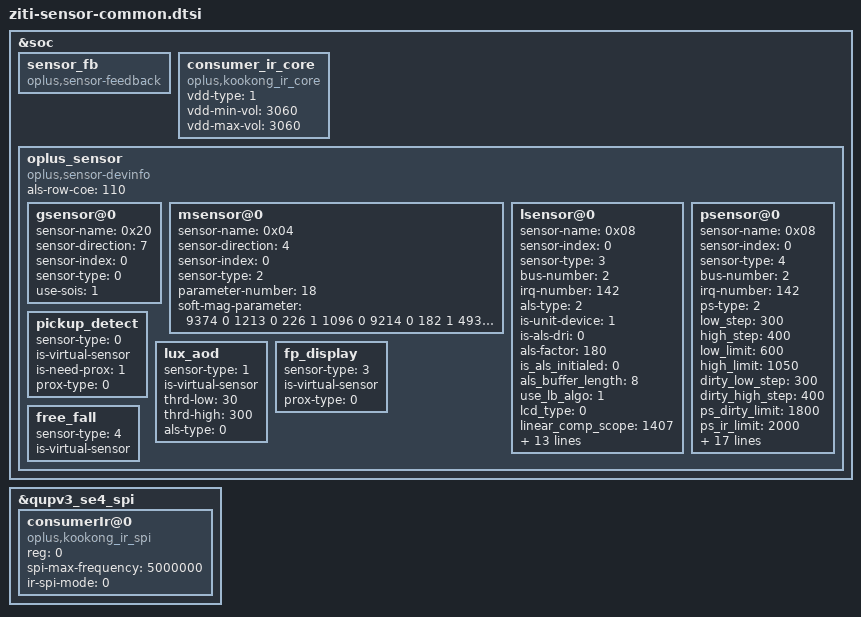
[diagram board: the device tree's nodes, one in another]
// SPDX-License-Identifier: GPL-2.0-only
/*
 * Copyright (C) 2018-2020 Oplus. All rights reserved.
 */

&soc {
        //#ifdef OPLUS_FEATURE_SENSOR_DRIVER
        sensor_fb: sensor_fb {
            compatible = "oplus,sensor-feedback";
        };
        consumer_ir_core: consumer_ir_core {
		compatible = "oplus,kookong_ir_core";
		status = "okay";

		vdd-type = <1>; /*0: internal LDO , 1: external LDO*/
		vdd-min-vol = <3060>;
		vdd-max-vol = <3060>;
	};
        /*enum sensor_id { OPLUS_ACCEL,OPLUS_GYRO,OPLUS_MAG,OPLUS_LIGHT,OPLUS_PROXIMITY,OPLUS_SAR,OPLUS_CT,OPLUS_BAROMETER,SENSORS_NUM};*/
        oplus_sensor: oplus_sensor {
                compatible = "oplus,sensor-devinfo";
                als-row-coe = <110>;
                /*enum {LSM6DSM = 0x01, BMI160 = 0x02, LSM6DS3 = 0x04, BMI260 = 0x08};*/
                gsensor@0 {
                        sensor-name = <0x20>;//ICM4X6XX
                        sensor-direction = <7>;
                        sensor-index = <0>;//source num
                        sensor-type = <0>;//OPLUS_ACCEL
                        use-sois = <1>;
                };
                /* enum {AKM0991X = 0x01, MMC5603 = 0x02};*/
                msensor@0 {
                        sensor-name = <0x04>;//MXG4300
                        sensor-direction = <4>;
                        sensor-index = <0>;
                        sensor-type = <2>;//OPLUS_MAG
                        parameter-number= <18>;
                        soft-mag-parameter = <9374 0 1213 0 226 1 1096 0 9214 0 182 1 493 0 677 1 10723 0>;//e00 sign e01 sign...
                };
                /*enum {STK3A5X=0x01,TCS3701=0x02,TCS3408=0x04,STK326X};*/
                /*enum {NORMAL=0x01,UNDER_LCD=0x02,VIRTUAL_UNDER_LCD=0x03}*/
		lsensor@0 {
			sensor-name = <0x08>;//stk3a6x
			sensor-index = <0>;
			sensor-type = <3>;//OPLUS_ALS
			bus-number = <2>;
			irq-number = <142>;
			als-type = <2>;//UNDER_LCD
			is-unit-device = <1>;
			is-als-dri = <0>;
			als-factor = <180>;
			is_als_initialed = <0>;
			als_buffer_length = <8>;
			use_lb_algo = <1>;
			lcd_type = <0>;
			linear_comp_scope = <1407>;
			linear_comp_intercept = <19873>;
			temp_lux = <0>;
			coef = <730>;
			bal_coef = <280>;
			ir_coef_stage_0 = <100>;
			ir_coef_stage_1 = <180>;
			ir_coef_stage_2 = <250>;
			ir_coef_stage_3 = <400>;
			ir_coef_val_0 = <1000>;
			ir_coef_val_1 = <500>;
			ir_coef_val_2 = <280>;
			ir_coef_val_3 = <180>;
			ir_coef_val_4 = <150>;
		};
		psensor@0 {
			sensor-name = <0x08>;//stk3a6x
			sensor-index = <0>;
			sensor-type = <4>;//OPLUS_PROXIMITY
			bus-number = <2>;
			irq-number = <142>;
			ps-type = <2>;
			low_step = <300>;
			high_step = <400>;
			low_limit = <600>;
			high_limit = <1050>;
			dirty_low_step = <300>;
			dirty_high_step = <400>;
			ps_dirty_limit = <1800>;
			ps_ir_limit = <2000>;
			ps_adjust_min = <0>;
			ps_adjust_max = <1850>;
			sampling_count = <5>;
			step_max = <400>;
			step_min = <100>;
			step_div = <2000>;
			anti_shake_delta = <70>;
			dynamic_cali_max = <2000>;
			raw2offset_radio = <1000>;
			offset_max = <60000>;
			offset_range_min = <0>;
			offset_range_max = <65535>;
			force_cali_limit = <2000>;
			cali_jitter_limit = <20>;
			cal_offset_margin = <3000>;
			parameter-number = <2>;
			sensor-reg = <0x03 0x60>; //override special reg
		};
                /*virtual sensor
                enum sensor_algo_id {
                        OPLUS_PICKUP_DETECT,
                        OPLUS_LUX_AOD,
                        OPLUS_TP_GESTURE,
                        OPLUS_FP_DISPLAY,
                        OPLUS_FREE_FALL,
                        OPLUS_CAMERA_PROTECT,
                        SENSOR_ALGO_NUM
                }*/
                pickup_detect {
                        sensor-type = <0>; //OPLUS_PICKUP_DETECT
                        is-virtual-sensor;
                        is-need-prox = <1>;
                        prox-type = <0>; // 0 - proximity; 1 - proximity_fake
                };
                lux_aod {
                        sensor-type = <1>; //OPLUS_LUX_AOD
                        is-virtual-sensor;
                        thrd-low = <30>;
                        thrd-high = <300>;
                        als-type = <0>; // 0 - wise_light; 1 - ambient_light
                };
                fp_display {
                        sensor-type = <3>; //OPLUS_FP_DISPLAY
                        is-virtual-sensor;
                        prox-type = <0>; // 0 - proximity; 1 - proximity_fake
                };
                free_fall {
                        sensor-type = <4>; //OPLUS_FREE_FALL
                        is-virtual-sensor;
                };
        };
        //#endif /*OPLUS_FEATURE_SENSOR_DRIVER*/
};

&qupv3_se4_spi {
	status = "ok";
	consumerIr@0 {
		compatible = "oplus,kookong_ir_spi";
		reg = <0>;
		status = "ok";
		spi-max-frequency = <5000000>;    /*4800000,9600000,15000000,19200000*/
		ir-spi-mode = <0>;
	};
};
